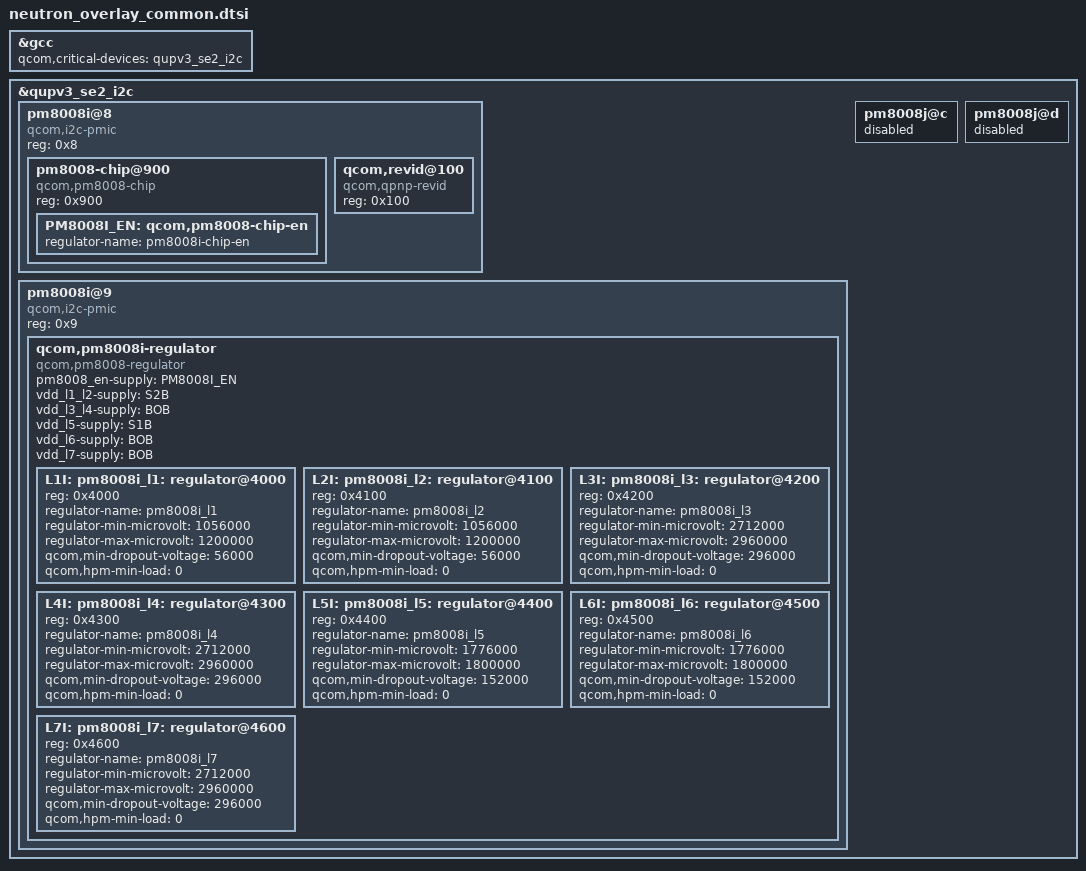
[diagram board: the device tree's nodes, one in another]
&gcc {
 	qcom,critical-devices = <&qupv3_se2_i2c>;
};

&qupv3_se2_i2c {
#address-cells = <1>;
#size-cells = <0>;
status = "ok";

pm8008i@8 {
	compatible = "qcom,i2c-pmic";
	reg = <0x8>;
	#address-cells = <1>;
	#size-cells = <0>;

	pm8008-chip@900 {
		compatible = "qcom,pm8008-chip";
		reg = <0x900>;

		PM8008I_EN: qcom,pm8008-chip-en {
			regulator-name = "pm8008i-chip-en";
			status = "ok";
		};
	};

        qcom,revid@100 {
		compatible = "qcom,qpnp-revid";
		reg = <0x100>;
	};
};

pm8008i@9 {
		compatible = "qcom,i2c-pmic";
		reg = <0x9>;
		#address-cells = <1>;
		#size-cells = <0>;

		qcom,pm8008i-regulator {
			compatible = "qcom,pm8008-regulator";
			#address-cells = <1>;
			#size-cells = <0>;

			pm8008_en-supply = <&PM8008I_EN>;
			vdd_l1_l2-supply = <&S2B>;
			vdd_l3_l4-supply = <&BOB>;
			vdd_l5-supply = <&S1B>;
			vdd_l6-supply = <&BOB>;
			vdd_l7-supply = <&BOB>;

			L1I: pm8008i_l1: regulator@4000 {
				reg = <0x4000>;
				regulator-name = "pm8008i_l1";
				regulator-min-microvolt = <1056000>;
				regulator-max-microvolt = <1200000>;
				qcom,min-dropout-voltage = <56000>;
				qcom,hpm-min-load = <0>;
			};

			L2I: pm8008i_l2: regulator@4100 {
				reg = <0x4100>;
				regulator-name = "pm8008i_l2";
				regulator-min-microvolt = <1056000>;
				regulator-max-microvolt = <1200000>;
				qcom,min-dropout-voltage = <56000>;
				qcom,hpm-min-load = <0>;
			};

			L3I: pm8008i_l3: regulator@4200 {
				reg = <0x4200>;
				regulator-name = "pm8008i_l3";
				regulator-min-microvolt = <2712000>;
				regulator-max-microvolt = <2960000>;
				qcom,min-dropout-voltage = <296000>;
				qcom,hpm-min-load = <0>;
			};

			L4I: pm8008i_l4: regulator@4300 {
				reg = <0x4300>;
				regulator-name = "pm8008i_l4";
				regulator-min-microvolt = <2712000>;
				regulator-max-microvolt = <2960000>;
				qcom,min-dropout-voltage = <296000>;
				qcom,hpm-min-load = <0>;
			};

			L5I: pm8008i_l5: regulator@4400 {
				reg = <0x4400>;
				regulator-name = "pm8008i_l5";
				regulator-min-microvolt = <1776000>;
				regulator-max-microvolt = <1800000>;
				qcom,min-dropout-voltage = <152000>;
				qcom,hpm-min-load = <0>;
			};

			L6I: pm8008i_l6: regulator@4500 {
				reg = <0x4500>;
				regulator-name = "pm8008i_l6";
				regulator-min-microvolt = <1776000>;
				regulator-max-microvolt = <1800000>;
				qcom,min-dropout-voltage = <152000>;
				qcom,hpm-min-load = <0>;
			};

			L7I: pm8008i_l7: regulator@4600 {
				reg = <0x4600>;
				regulator-name = "pm8008i_l7";
				regulator-min-microvolt = <2712000>;
				regulator-max-microvolt = <2960000>;
				qcom,min-dropout-voltage = <296000>;
				qcom,hpm-min-load = <0>;
			};
		};
	};

	pm8008j@c {
		status = "disabled";
	};

	pm8008j@d {
		status = "disabled";
	};
};
